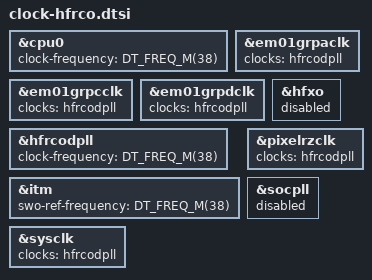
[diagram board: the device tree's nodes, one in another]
/*
 * Copyright (c) 2026 Silicon Laboratories Inc.
 *
 * SPDX-License-Identifier: Apache-2.0
 */

&cpu0 {
	clock-frequency = <DT_FREQ_M(38)>;
};

&em01grpaclk {
	clocks = <&hfrcodpll>;
};

&em01grpcclk {
	clocks = <&hfrcodpll>;
};

&em01grpdclk {
	clocks = <&hfrcodpll>;
};

&hfrcodpll {
	clock-frequency = <DT_FREQ_M(38)>;
	status = "okay";
};

&hfxo {
	status = "disabled";
};

&itm {
	swo-ref-frequency = <DT_FREQ_M(38)>;
};

&pixelrzclk {
	clocks = <&hfrcodpll>;
};

&socpll {
	status = "disabled";
};

&sysclk {
	clocks = <&hfrcodpll>;
};
